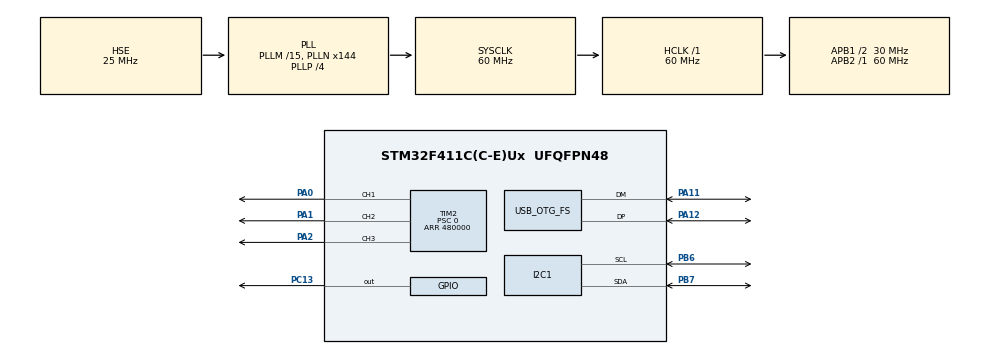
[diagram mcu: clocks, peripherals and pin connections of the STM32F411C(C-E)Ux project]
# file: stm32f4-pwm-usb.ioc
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FREERTOS.Queues01=pwmQueue,16,struct PwmLevels,0,Dynamic,NULL,NULL
FREERTOS.Tasks01=defaultTask,16,128,StartDefaultTask,Default,NULL,Dynamic,NULL,NULL;displayTask,24,128,StartDisplayTask,Default,NULL,Dynamic,NULL,NULL;pwmTask,32,128,StartPwmTask,Default,NULL,Dynamic,NULL,NULL
I2C1.I2C_Mode=I2C_Fast
Mcu.Family=STM32F4
Mcu.Name=STM32F411C(C-E)Ux
Mcu.Package=UFQFPN48
NVIC.OTG_FS_IRQn=true\:5\:0\:false\:false\:true\:true\:false\:true
NVIC.PriorityGroup=NVIC_PRIORITYGROUP_4
NVIC.TIM1_TRG_COM_TIM11_IRQn=true\:0\:0\:false\:false\:true\:false\:false\:true
NVIC.TimeBase=TIM1_TRG_COM_TIM11_IRQn
NVIC.TimeBaseIP=TIM11
PA0-WKUP.Signal=S_TIM2_CH1_ETR
PA1.Signal=S_TIM2_CH2
PA11.Mode=Device_Only
PA11.Signal=USB_OTG_FS_DM
PA12.Mode=Device_Only
PA12.Signal=USB_OTG_FS_DP
PA13.Mode=Serial_Wire
PA13.Signal=SYS_JTMS-SWDIO
PA14.Mode=Serial_Wire
PA14.Signal=SYS_JTCK-SWCLK
PA2.Signal=S_TIM2_CH3
PB6.GPIO_PuPdOD=GPIO_PULLUP
PB6.Mode=I2C
PB6.Signal=I2C1_SCL
PB7.GPIO_PuPdOD=GPIO_PULLUP
PB7.Mode=I2C
PB7.Signal=I2C1_SDA
PC13-ANTI_TAMP.GPIO_ModeDefaultOutputPP=GPIO_MODE_OUTPUT_OD
PC13-ANTI_TAMP.GPIO_PuPd=GPIO_PULLUP
PC13-ANTI_TAMP.PinState=GPIO_PIN_SET
PC13-ANTI_TAMP.Signal=GPIO_Output
PH0\ -\ OSC_IN.Mode=HSE-External-Oscillator
PH0\ -\ OSC_IN.Signal=RCC_OSC_IN
PH1\ -\ OSC_OUT.Mode=HSE-External-Oscillator
PH1\ -\ OSC_OUT.Signal=RCC_OSC_OUT
ProjectManager.HeapSize=0x200
ProjectManager.StackSize=0x400
ProjectManager.TargetToolchain=Makefile
RCC.48MHZClocksFreq_Value=48000000
RCC.AHBFreq_Value=60000000
RCC.APB1CLKDivider=RCC_HCLK_DIV2
RCC.APB1Freq_Value=30000000
RCC.APB1TimFreq_Value=60000000
RCC.APB2Freq_Value=60000000
RCC.APB2TimFreq_Value=60000000
RCC.CortexFreq_Value=60000000
RCC.HCLKFreq_Value=60000000
RCC.HSE_VALUE=25000000
RCC.HSI_VALUE=16000000
RCC.LSE_VALUE=32768
RCC.PLLM=15
RCC.PLLN=144
RCC.PLLP=RCC_PLLP_DIV4
RCC.PLLQ=5
RCC.SYSCLKFreq_VALUE=60000000
RCC.SYSCLKSource=RCC_SYSCLKSOURCE_PLLCLK
RCC.VCOOutputFreq_Value=240000000
SH.S_TIM2_CH1_ETR.0=TIM2_CH1,PWM Generation1 CH1
SH.S_TIM2_CH2.0=TIM2_CH2,PWM Generation2 CH2
SH.S_TIM2_CH3.0=TIM2_CH3,PWM Generation3 CH3
TIM2.Channel-PWM\ Generation1\ CH1=TIM_CHANNEL_1
TIM2.Channel-PWM\ Generation2\ CH2=TIM_CHANNEL_2
TIM2.Channel-PWM\ Generation3\ CH3=TIM_CHANNEL_3
TIM2.Period=480000
TIM2.Prescaler=0
USB_DEVICE.CLASS_NAME_FS=CDC
USB_DEVICE.VirtualMode=Cdc
USB_DEVICE.VirtualModeFS=Cdc_FS
USB_OTG_FS.VirtualMode=Device_Only
VP_FREERTOS_VS_CMSIS_V2.Mode=CMSIS_V2
VP_SYS_VS_tim11.Mode=TIM11
VP_USB_DEVICE_VS_USB_DEVICE_CDC_FS.Mode=CDC_FS
board=custom

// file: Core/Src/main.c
/* USER CODE BEGIN Header */
/**
  ******************************************************************************
  * @file           : main.c
  * @brief          : Main program body
  ******************************************************************************
  * @attention
  *
  * <h2><center>&copy; Copyright (c) 2021 STMicroelectronics.
  * All rights reserved.</center></h2>
  *
  * This software component is licensed by ST under Ultimate Liberty license
  * SLA0044, the "License"; You may not use this file except in compliance with
  * the License. You may obtain a copy of the License at:
  *                             www.st.com/SLA0044
  *
  ******************************************************************************
  */
/* USER CODE END Header */
#include "main.h"
#include "cmsis_os.h"
#include "usb_device.h"

/* USER CODE BEGIN Includes */
#include "display.h"
#include "pwm.h"
/* USER CODE END Includes */

I2C_HandleTypeDef hi2c1;

TIM_HandleTypeDef htim2;

/* Definitions for defaultTask */
osThreadId_t defaultTaskHandle;
const osThreadAttr_t defaultTask_attributes = {
  .name = "defaultTask",
  .stack_size = 128 * 4,
  .priority = (osPriority_t) osPriorityBelowNormal,
};
/* Definitions for displayTask */
osThreadId_t displayTaskHandle;
const osThreadAttr_t displayTask_attributes = {
  .name = "displayTask",
  .stack_size = 128 * 4,
  .priority = (osPriority_t) osPriorityNormal,
};
/* Definitions for pwmTask */
osThreadId_t pwmTaskHandle;
const osThreadAttr_t pwmTask_attributes = {
  .name = "pwmTask",
  .stack_size = 128 * 4,
  .priority = (osPriority_t) osPriorityAboveNormal,
};
/* Definitions for pwmQueue */
osMessageQueueId_t pwmQueueHandle;
const osMessageQueueAttr_t pwmQueue_attributes = {
  .name = "pwmQueue"
};

void SystemClock_Config(void);
static void MX_GPIO_Init(void);
static void MX_I2C1_Init(void);
static void MX_TIM2_Init(void);
void StartDefaultTask(void *argument);
void StartDisplayTask(void *argument);
void StartPwmTask(void *argument);

int main(void)
{

  /* MCU Configuration--------------------------------------------------------*/

  /* Reset of all peripherals, Initializes the Flash interface and the Systick. */
  HAL_Init();

  /* Configure the system clock */
  SystemClock_Config();

  /* Initialize all configured peripherals */
  MX_GPIO_Init();
  MX_I2C1_Init();
  MX_TIM2_Init();

  /* Init scheduler */
  osKernelInitialize();

  /* Create the queue(s) */
  /* creation of pwmQueue */
  pwmQueueHandle = osMessageQueueNew (16, sizeof(struct pwm_levels), &pwmQueue_attributes);

  /* Create the thread(s) */
  /* creation of defaultTask */
  defaultTaskHandle = osThreadNew(StartDefaultTask, NULL, &defaultTask_attributes);

  /* creation of displayTask */
  displayTaskHandle = osThreadNew(StartDisplayTask, NULL, &displayTask_attributes);

  /* creation of pwmTask */
  pwmTaskHandle = osThreadNew(StartPwmTask, NULL, &pwmTask_attributes);

  /* Start scheduler */
  osKernelStart();

  /* We should never get here as control is now taken by the scheduler */
  /* Infinite loop */
  while (1)
  {

  }
}

void SystemClock_Config(void)
{
  RCC_OscInitTypeDef RCC_OscInitStruct = {0};
  RCC_ClkInitTypeDef RCC_ClkInitStruct = {0};

  /** Configure the main internal regulator output voltage
  */
  __HAL_RCC_PWR_CLK_ENABLE();
  __HAL_PWR_VOLTAGESCALING_CONFIG(PWR_REGULATOR_VOLTAGE_SCALE1);
  /** Initializes the RCC Oscillators according to the specified parameters
  * in the RCC_OscInitTypeDef structure.
  */
  RCC_OscInitStruct.OscillatorType = RCC_OSCILLATORTYPE_HSE;
  RCC_OscInitStruct.HSEState = RCC_HSE_ON;
  RCC_OscInitStruct.PLL.PLLState = RCC_PLL_ON;
  RCC_OscInitStruct.PLL.PLLSource = RCC_PLLSOURCE_HSE;
  RCC_OscInitStruct.PLL.PLLM = 15;
  RCC_OscInitStruct.PLL.PLLN = 144;
  RCC_OscInitStruct.PLL.PLLP = RCC_PLLP_DIV4;
  RCC_OscInitStruct.PLL.PLLQ = 5;
  if (HAL_RCC_OscConfig(&RCC_OscInitStruct) != HAL_OK)
  {
    Error_Handler();
  }
  /** Initializes the CPU, AHB and APB buses clocks
  */
  RCC_ClkInitStruct.ClockType = RCC_CLOCKTYPE_HCLK|RCC_CLOCKTYPE_SYSCLK
                              |RCC_CLOCKTYPE_PCLK1|RCC_CLOCKTYPE_PCLK2;
  RCC_ClkInitStruct.SYSCLKSource = RCC_SYSCLKSOURCE_PLLCLK;
  RCC_ClkInitStruct.AHBCLKDivider = RCC_SYSCLK_DIV1;
  RCC_ClkInitStruct.APB1CLKDivider = RCC_HCLK_DIV2;
  RCC_ClkInitStruct.APB2CLKDivider = RCC_HCLK_DIV1;

  if (HAL_RCC_ClockConfig(&RCC_ClkInitStruct, FLASH_LATENCY_1) != HAL_OK)
  {
    Error_Handler();
  }
}

static void MX_I2C1_Init(void)
{

  hi2c1.Instance = I2C1;
  hi2c1.Init.ClockSpeed = 400000;
  hi2c1.Init.DutyCycle = I2C_DUTYCYCLE_2;
  hi2c1.Init.OwnAddress1 = 0;
  hi2c1.Init.AddressingMode = I2C_ADDRESSINGMODE_7BIT;
  hi2c1.Init.DualAddressMode = I2C_DUALADDRESS_DISABLE;
  hi2c1.Init.OwnAddress2 = 0;
  hi2c1.Init.GeneralCallMode = I2C_GENERALCALL_DISABLE;
  hi2c1.Init.NoStretchMode = I2C_NOSTRETCH_DISABLE;
  if (HAL_I2C_Init(&hi2c1) != HAL_OK)
  {
    Error_Handler();
  }

}

static void MX_TIM2_Init(void)
{

  TIM_MasterConfigTypeDef sMasterConfig = {0};
  TIM_OC_InitTypeDef sConfigOC = {0};

  htim2.Instance = TIM2;
  htim2.Init.Prescaler = 0;
  htim2.Init.CounterMode = TIM_COUNTERMODE_UP;
  htim2.Init.Period = 480000;
  htim2.Init.ClockDivision = TIM_CLOCKDIVISION_DIV1;
  htim2.Init.AutoReloadPreload = TIM_AUTORELOAD_PRELOAD_DISABLE;
  if (HAL_TIM_PWM_Init(&htim2) != HAL_OK)
  {
    Error_Handler();
  }
  sMasterConfig.MasterOutputTrigger = TIM_TRGO_RESET;
  sMasterConfig.MasterSlaveMode = TIM_MASTERSLAVEMODE_DISABLE;
  if (HAL_TIMEx_MasterConfigSynchronization(&htim2, &sMasterConfig) != HAL_OK)
  {
    Error_Handler();
  }
  sConfigOC.OCMode = TIM_OCMODE_PWM1;
  sConfigOC.Pulse = 0;
  sConfigOC.OCPolarity = TIM_OCPOLARITY_HIGH;
  sConfigOC.OCFastMode = TIM_OCFAST_DISABLE;
  if (HAL_TIM_PWM_ConfigChannel(&htim2, &sConfigOC, TIM_CHANNEL_1) != HAL_OK)
  {
    Error_Handler();
  }
  if (HAL_TIM_PWM_ConfigChannel(&htim2, &sConfigOC, TIM_CHANNEL_2) != HAL_OK)
  {
    Error_Handler();
  }
  if (HAL_TIM_PWM_ConfigChannel(&htim2, &sConfigOC, TIM_CHANNEL_3) != HAL_OK)
  {
    Error_Handler();
  }
  HAL_TIM_MspPostInit(&htim2);

}

static void MX_GPIO_Init(void)
{
  GPIO_InitTypeDef GPIO_InitStruct = {0};

  /* GPIO Ports Clock Enable */
  __HAL_RCC_GPIOC_CLK_ENABLE();
  __HAL_RCC_GPIOH_CLK_ENABLE();
  __HAL_RCC_GPIOA_CLK_ENABLE();
  __HAL_RCC_GPIOB_CLK_ENABLE();

  /*Configure GPIO pin Output Level */
  HAL_GPIO_WritePin(GPIOC, GPIO_PIN_13, GPIO_PIN_SET);

  /*Configure GPIO pin : PC13 */
  GPIO_InitStruct.Pin = GPIO_PIN_13;
  GPIO_InitStruct.Mode = GPIO_MODE_OUTPUT_OD;
  GPIO_InitStruct.Pull = GPIO_PULLUP;
  GPIO_InitStruct.Speed = GPIO_SPEED_FREQ_LOW;
  HAL_GPIO_Init(GPIOC, &GPIO_InitStruct);

}

void StartDefaultTask(void *argument)
{
  /* init code for USB_DEVICE */
  MX_USB_DEVICE_Init();
  /* USER CODE BEGIN 5 */
  /* Infinite loop */
  for(;;)
  {
    printf("Heartbeat\r\n");
    HAL_GPIO_TogglePin(GPIOC, GPIO_PIN_13);
    osDelay(1000);
  }
  /* USER CODE END 5 */
}

void StartDisplayTask(void *argument)
{
  /* USER CODE BEGIN StartDisplayTask */
  /* Infinite loop */
  DisplayTaskMain();
  /* USER CODE END StartDisplayTask */
}

void StartPwmTask(void *argument)
{
  /* USER CODE BEGIN StartPwmTask */
  pwm_task_main();
  /* USER CODE END StartPwmTask */
}

 /**
  * @brief  Period elapsed callback in non blocking mode
  * @note   This function is called  when TIM11 interrupt took place, inside
  * HAL_TIM_IRQHandler(). It makes a direct call to HAL_IncTick() to increment
  * a global variable "uwTick" used as application time base.
  * @param  htim : TIM handle
  * @retval None
  */
void HAL_TIM_PeriodElapsedCallback(TIM_HandleTypeDef *htim)
{
  if (htim->Instance == TIM11) {
    HAL_IncTick();
  }
}

void Error_Handler(void)
{
  __disable_irq();
  while (1)
  {
  }
}

/************************ (C) COPYRIGHT STMicroelectronics *****END OF FILE****/
